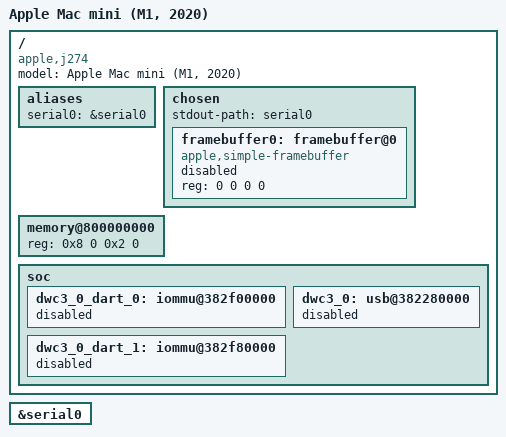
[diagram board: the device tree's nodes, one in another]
// SPDX-License-Identifier: GPL-2.0+ OR MIT
/*
 * Apple Mac mini (M1, 2020)
 *
 * target-type: J274
 *
 * Copyright The Asahi Linux Contributors
 */

/dts-v1/;

#include "t8103.dtsi"

/ {
	compatible = "apple,j274", "apple,t8103", "apple,arm-platform";
	model = "Apple Mac mini (M1, 2020)";

	aliases {
		serial0 = &serial0;
	};

	chosen {
		#address-cells = <2>;
		#size-cells = <2>;
		ranges;

		stdout-path = "serial0";

		framebuffer0: framebuffer@0 {
			compatible = "apple,simple-framebuffer", "simple-framebuffer";
			reg = <0 0 0 0>; /* To be filled by loader */
			/* Format properties will be added by loader */
			status = "disabled";
		};
	};

	memory@800000000 {
		device_type = "memory";
		reg = <0x8 0 0x2 0>; /* To be filled by loader */
	};

        soc {
            /* Disable the first USB port */
            dwc3_0_dart_0: iommu@382f00000 {
                status = "disabled";
            };
            dwc3_0_dart_1: iommu@382f80000 {
                status = "disabled";
            };
            dwc3_0: usb@382280000{
                status = "disabled";
            };
        };
};

&serial0 {
	status = "okay";
};
